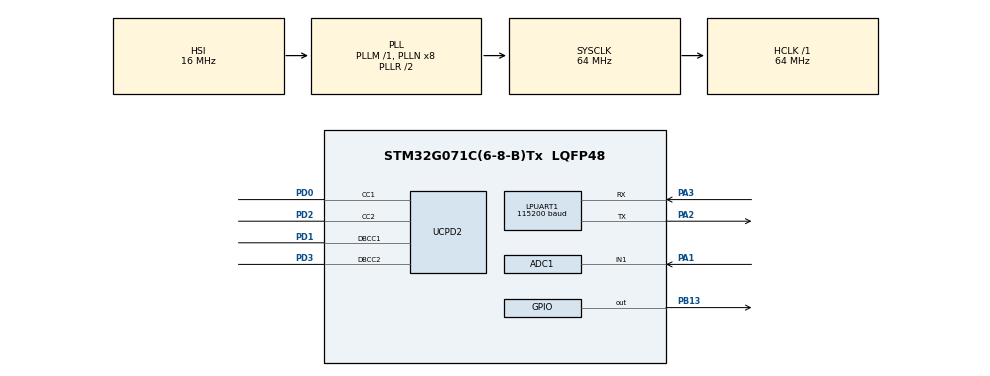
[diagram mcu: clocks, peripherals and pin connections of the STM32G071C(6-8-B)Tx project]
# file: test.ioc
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ADC1.Channel-1\#ChannelRegularConversion=ADC_CHANNEL_1
ADC1.ContinuousConvMode=ENABLE
ADC1.DMAContinuousRequests=ENABLE
ADC1.NbrOfConversion=1
ADC1.NbrOfConversionFlag=1
ADC1.OversamplingMode=DISABLE
ADC1.Rank-1\#ChannelRegularConversion=1
ADC1.SamplingTime-1\#ChannelRegularConversion=ADC_SAMPLINGTIME_COMMON_1
ADC1.SamplingTimeCommon1=ADC_SAMPLETIME_160CYCLES_5
ADC1.SamplingTimeCommon2=ADC_SAMPLETIME_160CYCLES_5
ADC1.master=1
Dma.ADC1.0.Direction=DMA_PERIPH_TO_MEMORY
Dma.ADC1.0.EventEnable=DISABLE
Dma.ADC1.0.Instance=DMA1_Channel1
Dma.ADC1.0.MemDataAlignment=DMA_MDATAALIGN_HALFWORD
Dma.ADC1.0.MemInc=DMA_MINC_ENABLE
Dma.ADC1.0.Mode=DMA_CIRCULAR
Dma.ADC1.0.PeriphDataAlignment=DMA_PDATAALIGN_HALFWORD
Dma.ADC1.0.PeriphInc=DMA_PINC_DISABLE
Dma.ADC1.0.Polarity=HAL_DMAMUX_REQ_GEN_RISING
Dma.ADC1.0.Priority=DMA_PRIORITY_LOW
Dma.ADC1.0.RequestNumber=1
Dma.ADC1.0.SignalID=NONE
Dma.ADC1.0.SyncEnable=DISABLE
Dma.ADC1.0.SyncPolarity=HAL_DMAMUX_SYNC_NO_EVENT
Dma.ADC1.0.SyncRequestNumber=1
Dma.ADC1.0.SyncSignalID=NONE
Dma.LPUART1_TX.3.Direction=DMA_MEMORY_TO_PERIPH
Dma.LPUART1_TX.3.EventEnable=DISABLE
Dma.LPUART1_TX.3.Instance=DMA1_Channel4
Dma.LPUART1_TX.3.MemDataAlignment=DMA_MDATAALIGN_BYTE
Dma.LPUART1_TX.3.MemInc=DMA_MINC_ENABLE
Dma.LPUART1_TX.3.Mode=DMA_NORMAL
Dma.LPUART1_TX.3.PeriphDataAlignment=DMA_PDATAALIGN_BYTE
Dma.LPUART1_TX.3.PeriphInc=DMA_PINC_DISABLE
Dma.LPUART1_TX.3.Polarity=HAL_DMAMUX_REQ_GEN_RISING
Dma.LPUART1_TX.3.Priority=DMA_PRIORITY_LOW
Dma.LPUART1_TX.3.RequestNumber=1
Dma.LPUART1_TX.3.SignalID=NONE
Dma.LPUART1_TX.3.SyncEnable=DISABLE
Dma.LPUART1_TX.3.SyncPolarity=HAL_DMAMUX_SYNC_NO_EVENT
Dma.LPUART1_TX.3.SyncRequestNumber=1
Dma.LPUART1_TX.3.SyncSignalID=NONE
Dma.Request0=ADC1
Dma.Request1=UCPD2_RX
Dma.Request2=UCPD2_TX
Dma.Request3=LPUART1_TX
Dma.UCPD2_RX.1.Direction=DMA_PERIPH_TO_MEMORY
Dma.UCPD2_RX.1.EventEnable=DISABLE
Dma.UCPD2_RX.1.Instance=DMA1_Channel2
Dma.UCPD2_RX.1.MemDataAlignment=DMA_MDATAALIGN_BYTE
Dma.UCPD2_RX.1.MemInc=DMA_MINC_ENABLE
Dma.UCPD2_RX.1.Mode=DMA_NORMAL
Dma.UCPD2_RX.1.PeriphDataAlignment=DMA_PDATAALIGN_BYTE
Dma.UCPD2_RX.1.PeriphInc=DMA_PINC_DISABLE
Dma.UCPD2_RX.1.Polarity=HAL_DMAMUX_REQ_GEN_RISING
Dma.UCPD2_RX.1.Priority=DMA_PRIORITY_LOW
Dma.UCPD2_RX.1.RequestNumber=1
Dma.UCPD2_RX.1.SignalID=NONE
Dma.UCPD2_RX.1.SyncEnable=DISABLE
Dma.UCPD2_RX.1.SyncPolarity=HAL_DMAMUX_SYNC_NO_EVENT
Dma.UCPD2_RX.1.SyncRequestNumber=1
Dma.UCPD2_RX.1.SyncSignalID=NONE
Dma.UCPD2_TX.2.Direction=DMA_MEMORY_TO_PERIPH
Dma.UCPD2_TX.2.EventEnable=DISABLE
Dma.UCPD2_TX.2.Instance=DMA1_Channel3
Dma.UCPD2_TX.2.MemDataAlignment=DMA_MDATAALIGN_BYTE
Dma.UCPD2_TX.2.MemInc=DMA_MINC_ENABLE
Dma.UCPD2_TX.2.Mode=DMA_NORMAL
Dma.UCPD2_TX.2.PeriphDataAlignment=DMA_PDATAALIGN_BYTE
Dma.UCPD2_TX.2.PeriphInc=DMA_PINC_DISABLE
Dma.UCPD2_TX.2.Polarity=HAL_DMAMUX_REQ_GEN_RISING
Dma.UCPD2_TX.2.Priority=DMA_PRIORITY_LOW
Dma.UCPD2_TX.2.RequestNumber=1
Dma.UCPD2_TX.2.SignalID=NONE
Dma.UCPD2_TX.2.SyncEnable=DISABLE
Dma.UCPD2_TX.2.SyncPolarity=HAL_DMAMUX_SYNC_NO_EVENT
Dma.UCPD2_TX.2.SyncRequestNumber=1
Dma.UCPD2_TX.2.SyncSignalID=NONE
FREERTOS.Tasks01=defaultTask,0,128,StartDefaultTask,Default,NULL,Dynamic,NULL,NULL
FREERTOS.configTOTAL_HEAP_SIZE=5000
GUI_INTERFACE.HWBoardVersionName=OtterBoard
GUI_INTERFACE.PDTypeName=V1.0
LPUART1.BaudRate=115200
LPUART1.WordLength=UART_WORDLENGTH_8B
Mcu.Family=STM32G0
Mcu.Name=STM32G071C(6-8-B)Tx
Mcu.Package=LQFP48
Mcu.UserConstants=VDDAAPPLI,3300
NVIC.DMA1_Ch4_7_DMAMUX1_OVR_IRQn=true\:3\:0\:false\:false\:true\:true\:false\:true
NVIC.DMA1_Channel1_IRQn=true\:3\:0\:false\:false\:true\:true\:false\:true
NVIC.DMA1_Channel2_3_IRQn=true\:3\:0\:false\:false\:true\:true\:false\:true
NVIC.UCPD1_2_IRQn=true\:3\:0\:false\:false\:true\:true\:true\:false
NVIC.USART3_4_LPUART1_IRQn=true\:3\:0\:false\:false\:true\:true\:true\:true
PA1.Mode=IN1
PA1.Signal=ADC1_IN1
PA13.Mode=Serial_Wire
PA13.Signal=SYS_SWDIO
PA14-BOOT0.Mode=Serial_Wire
PA14-BOOT0.Signal=SYS_SWCLK
PA2.Mode=Asynchronous
PA2.Signal=LPUART1_TX
PA3.Mode=Asynchronous
PA3.Signal=LPUART1_RX
PB13.Signal=GPIO_Output
PD0.Mode=Sink_AllSignals
PD0.Signal=UCPD2_CC1
PD1.Mode=EnableDeadBattery
PD1.Signal=UCPD2_DBCC1
PD2.Mode=Sink_AllSignals
PD2.Signal=UCPD2_CC2
PD3.Mode=EnableDeadBattery
PD3.Signal=UCPD2_DBCC2
ProjectManager.HeapSize=0x200
ProjectManager.StackSize=0x400
ProjectManager.TargetToolchain=Makefile
RCC.ADCCLockSelection=RCC_ADCCLKSOURCE_PLLADC
RCC.ADCFreq_Value=64000000
RCC.AHBFreq_Value=64000000
RCC.CortexFreq_Value=64000000
RCC.EXTERNAL_CLOCK_VALUE=48000
RCC.HCLKFreq_Value=64000000
RCC.HSE_VALUE=8000000
RCC.HSI_VALUE=16000000
RCC.LSE_VALUE=32768
RCC.SYSCLKFreq_VALUE=64000000
RCC.SYSCLKSource=RCC_SYSCLKSOURCE_PLLCLK
RCC.VCOOutputFreq_Value=128000000
USBPD.PE_SpecRevision_P0=USBPD_SPECIFICATION_REV3
USBPD.PE_SupportedSOPapos_P0=USBPD_SUPPORTED_SOP_SOP1
VP_FREERTOS_VS_CMSIS_V1.Mode=CMSIS_V1
VP_GUI_INTERFACE_VS_gui_interface.Mode=GUI_INTERFACE
VP_SYS_VS_DBSignals.Mode=DisableDeadBatterySignals
VP_TRACER_EMB_VS_traceremb_lpuart1.Mode=TRACER_EMB_LPUART1
VP_USBPD_VS_USBPD2.Mode=USBPD_P0
VP_USBPD_VS_usbpd_tim1.Mode=TIM1
VP_USBPD_VS_usbpd_traceremb.Mode=TRACER_EMB
board=custom

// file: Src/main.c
/* USER CODE BEGIN Header */
/**
  ******************************************************************************
  * @file           : main.c
  * @brief          : Main program body
  ******************************************************************************
  * @attention
  *
  * <h2><center>&copy; Copyright (c) 2020 STMicroelectronics.
  * All rights reserved.</center></h2>
  *
  * This software component is licensed by ST under BSD 3-Clause license,
  * the "License"; You may not use this file except in compliance with the
  * License. You may obtain a copy of the License at:
  *                        opensource.org/licenses/BSD-3-Clause
  *
  ******************************************************************************
  */
/* USER CODE END Header */

#include "main.h"
#include "cmsis_os.h"
#include "usbpd.h"

/* USER CODE BEGIN PM */
uint16_t adc;
float vin;
/* USER CODE END PM */

ADC_HandleTypeDef hadc1;
DMA_HandleTypeDef hdma_adc1;

UART_HandleTypeDef hlpuart1;
DMA_HandleTypeDef hdma_lpuart1_tx;

osThreadId defaultTaskHandle;

void SystemClock_Config(void);
static void MX_GPIO_Init(void);
static void MX_DMA_Init(void);
static void MX_ADC1_Init(void);
static void MX_UCPD2_Init(void);
static void MX_LPUART1_UART_Init(void);
void StartDefaultTask(void const * argument);

int main(void)
{

  /* MCU Configuration--------------------------------------------------------*/

  /* Reset of all peripherals, Initializes the Flash interface and the Systick. */
  HAL_Init();

  /* Configure the system clock */
  SystemClock_Config();

  /* Initialize all configured peripherals */
  MX_GPIO_Init();
  MX_DMA_Init();
  MX_ADC1_Init();
  MX_UCPD2_Init();
  MX_USBPD_Init();
  MX_LPUART1_UART_Init();
  /* USER CODE BEGIN 2 */
  HAL_ADCEx_Calibration_Start(&hadc1);
  HAL_ADC_Start(&hadc1);
  /* USER CODE END 2 */
  /* USBPD initialisation ---------------------------------*/
  MX_USBPD_Init();

  /* Create the thread(s) */
  /* definition and creation of defaultTask */
  osThreadDef(defaultTask, StartDefaultTask, osPriorityNormal, 0, 128);
  defaultTaskHandle = osThreadCreate(osThread(defaultTask), NULL);

  /* Start scheduler */
  osKernelStart();

  /* We should never get here as control is now taken by the scheduler */

  /* Infinite loop */
  while (1)
  {

  }
}

void SystemClock_Config(void)
{
  RCC_OscInitTypeDef RCC_OscInitStruct = {0};
  RCC_ClkInitTypeDef RCC_ClkInitStruct = {0};
  RCC_PeriphCLKInitTypeDef PeriphClkInit = {0};

  /** Configure the main internal regulator output voltage
  */
  HAL_PWREx_ControlVoltageScaling(PWR_REGULATOR_VOLTAGE_SCALE1);
  /** Initializes the CPU, AHB and APB busses clocks
  */
  RCC_OscInitStruct.OscillatorType = RCC_OSCILLATORTYPE_HSI;
  RCC_OscInitStruct.HSIState = RCC_HSI_ON;
  RCC_OscInitStruct.HSIDiv = RCC_HSI_DIV1;
  RCC_OscInitStruct.HSICalibrationValue = RCC_HSICALIBRATION_DEFAULT;
  RCC_OscInitStruct.PLL.PLLState = RCC_PLL_ON;
  RCC_OscInitStruct.PLL.PLLSource = RCC_PLLSOURCE_HSI;
  RCC_OscInitStruct.PLL.PLLM = RCC_PLLM_DIV1;
  RCC_OscInitStruct.PLL.PLLN = 8;
  RCC_OscInitStruct.PLL.PLLP = RCC_PLLP_DIV2;
  RCC_OscInitStruct.PLL.PLLQ = RCC_PLLQ_DIV2;
  RCC_OscInitStruct.PLL.PLLR = RCC_PLLR_DIV2;
  if (HAL_RCC_OscConfig(&RCC_OscInitStruct) != HAL_OK)
  {
    Error_Handler();
  }
  /** Initializes the CPU, AHB and APB busses clocks
  */
  RCC_ClkInitStruct.ClockType = RCC_CLOCKTYPE_HCLK|RCC_CLOCKTYPE_SYSCLK
                              |RCC_CLOCKTYPE_PCLK1;
  RCC_ClkInitStruct.SYSCLKSource = RCC_SYSCLKSOURCE_PLLCLK;
  RCC_ClkInitStruct.AHBCLKDivider = RCC_SYSCLK_DIV1;
  RCC_ClkInitStruct.APB1CLKDivider = RCC_HCLK_DIV1;

  if (HAL_RCC_ClockConfig(&RCC_ClkInitStruct, FLASH_LATENCY_2) != HAL_OK)
  {
    Error_Handler();
  }
  /** Initializes the peripherals clocks
  */
  PeriphClkInit.PeriphClockSelection = RCC_PERIPHCLK_LPUART1|RCC_PERIPHCLK_ADC;
  PeriphClkInit.Lpuart1ClockSelection = RCC_LPUART1CLKSOURCE_PCLK1;
  PeriphClkInit.AdcClockSelection = RCC_ADCCLKSOURCE_PLLADC;
  if (HAL_RCCEx_PeriphCLKConfig(&PeriphClkInit) != HAL_OK)
  {
    Error_Handler();
  }
}

static void MX_ADC1_Init(void)
{

  ADC_ChannelConfTypeDef sConfig = {0};

  /** Configure the global features of the ADC (Clock, Resolution, Data Alignment and number of conversion)
  */
  hadc1.Instance = ADC1;
  hadc1.Init.ClockPrescaler = ADC_CLOCK_SYNC_PCLK_DIV4;
  hadc1.Init.Resolution = ADC_RESOLUTION_12B;
  hadc1.Init.DataAlign = ADC_DATAALIGN_RIGHT;
  hadc1.Init.ScanConvMode = ADC_SCAN_DISABLE;
  hadc1.Init.EOCSelection = ADC_EOC_SINGLE_CONV;
  hadc1.Init.LowPowerAutoWait = DISABLE;
  hadc1.Init.LowPowerAutoPowerOff = DISABLE;
  hadc1.Init.ContinuousConvMode = ENABLE;
  hadc1.Init.NbrOfConversion = 1;
  hadc1.Init.DiscontinuousConvMode = DISABLE;
  hadc1.Init.ExternalTrigConv = ADC_SOFTWARE_START;
  hadc1.Init.ExternalTrigConvEdge = ADC_EXTERNALTRIGCONVEDGE_NONE;
  hadc1.Init.DMAContinuousRequests = DISABLE;
  hadc1.Init.Overrun = ADC_OVR_DATA_PRESERVED;
  hadc1.Init.SamplingTimeCommon1 = ADC_SAMPLETIME_160CYCLES_5;
  hadc1.Init.SamplingTimeCommon2 = ADC_SAMPLETIME_160CYCLES_5;
  hadc1.Init.OversamplingMode = DISABLE;
  hadc1.Init.TriggerFrequencyMode = ADC_TRIGGER_FREQ_HIGH;
  if (HAL_ADC_Init(&hadc1) != HAL_OK)
  {
    Error_Handler();
  }
  /** Configure Regular Channel
  */
  sConfig.Channel = ADC_CHANNEL_1;
  sConfig.Rank = ADC_REGULAR_RANK_1;
  sConfig.SamplingTime = ADC_SAMPLINGTIME_COMMON_1;
  if (HAL_ADC_ConfigChannel(&hadc1, &sConfig) != HAL_OK)
  {
    Error_Handler();
  }

}

static void MX_LPUART1_UART_Init(void)
{

  hlpuart1.Instance = LPUART1;
  hlpuart1.Init.BaudRate = 209700;
  hlpuart1.Init.WordLength = UART_WORDLENGTH_7B;
  hlpuart1.Init.StopBits = UART_STOPBITS_1;
  hlpuart1.Init.Parity = UART_PARITY_NONE;
  hlpuart1.Init.Mode = UART_MODE_TX_RX;
  hlpuart1.Init.HwFlowCtl = UART_HWCONTROL_NONE;
  hlpuart1.Init.OneBitSampling = UART_ONE_BIT_SAMPLE_DISABLE;
  hlpuart1.Init.ClockPrescaler = UART_PRESCALER_DIV1;
  hlpuart1.AdvancedInit.AdvFeatureInit = UART_ADVFEATURE_NO_INIT;
  hlpuart1.FifoMode = UART_FIFOMODE_DISABLE;
  if (HAL_UART_Init(&hlpuart1) != HAL_OK)
  {
    Error_Handler();
  }
  if (HAL_UARTEx_SetTxFifoThreshold(&hlpuart1, UART_TXFIFO_THRESHOLD_1_8) != HAL_OK)
  {
    Error_Handler();
  }
  if (HAL_UARTEx_SetRxFifoThreshold(&hlpuart1, UART_RXFIFO_THRESHOLD_1_8) != HAL_OK)
  {
    Error_Handler();
  }
  if (HAL_UARTEx_DisableFifoMode(&hlpuart1) != HAL_OK)
  {
    Error_Handler();
  }

}

static void MX_UCPD2_Init(void)
{

  /* Peripheral clock enable */
  LL_APB1_GRP1_EnableClock(LL_APB1_GRP1_PERIPH_UCPD2);

  /* UCPD2 DMA Init */

  /* UCPD2_RX Init */
  LL_DMA_SetPeriphRequest(DMA1, LL_DMA_CHANNEL_2, LL_DMAMUX_REQ_UCPD2_RX);

  LL_DMA_SetDataTransferDirection(DMA1, LL_DMA_CHANNEL_2, LL_DMA_DIRECTION_PERIPH_TO_MEMORY);

  LL_DMA_SetChannelPriorityLevel(DMA1, LL_DMA_CHANNEL_2, LL_DMA_PRIORITY_LOW);

  LL_DMA_SetMode(DMA1, LL_DMA_CHANNEL_2, LL_DMA_MODE_NORMAL);

  LL_DMA_SetPeriphIncMode(DMA1, LL_DMA_CHANNEL_2, LL_DMA_PERIPH_NOINCREMENT);

  LL_DMA_SetMemoryIncMode(DMA1, LL_DMA_CHANNEL_2, LL_DMA_MEMORY_INCREMENT);

  LL_DMA_SetPeriphSize(DMA1, LL_DMA_CHANNEL_2, LL_DMA_PDATAALIGN_BYTE);

  LL_DMA_SetMemorySize(DMA1, LL_DMA_CHANNEL_2, LL_DMA_MDATAALIGN_BYTE);

  /* UCPD2_TX Init */
  LL_DMA_SetPeriphRequest(DMA1, LL_DMA_CHANNEL_3, LL_DMAMUX_REQ_UCPD2_TX);

  LL_DMA_SetDataTransferDirection(DMA1, LL_DMA_CHANNEL_3, LL_DMA_DIRECTION_MEMORY_TO_PERIPH);

  LL_DMA_SetChannelPriorityLevel(DMA1, LL_DMA_CHANNEL_3, LL_DMA_PRIORITY_LOW);

  LL_DMA_SetMode(DMA1, LL_DMA_CHANNEL_3, LL_DMA_MODE_NORMAL);

  LL_DMA_SetPeriphIncMode(DMA1, LL_DMA_CHANNEL_3, LL_DMA_PERIPH_NOINCREMENT);

  LL_DMA_SetMemoryIncMode(DMA1, LL_DMA_CHANNEL_3, LL_DMA_MEMORY_INCREMENT);

  LL_DMA_SetPeriphSize(DMA1, LL_DMA_CHANNEL_3, LL_DMA_PDATAALIGN_BYTE);

  LL_DMA_SetMemorySize(DMA1, LL_DMA_CHANNEL_3, LL_DMA_MDATAALIGN_BYTE);

  /* UCPD2 interrupt Init */
  NVIC_SetPriority(UCPD1_2_IRQn, 3);
  NVIC_EnableIRQ(UCPD1_2_IRQn);

}

static void MX_DMA_Init(void)
{

  /* DMA controller clock enable */
  __HAL_RCC_DMA1_CLK_ENABLE();

  /* DMA interrupt init */
  /* DMA1_Channel1_IRQn interrupt configuration */
  HAL_NVIC_SetPriority(DMA1_Channel1_IRQn, 3, 0);
  HAL_NVIC_EnableIRQ(DMA1_Channel1_IRQn);
  /* DMA1_Channel2_3_IRQn interrupt configuration */
  NVIC_SetPriority(DMA1_Channel2_3_IRQn, 3);
  NVIC_EnableIRQ(DMA1_Channel2_3_IRQn);
  /* DMA1_Ch4_7_DMAMUX1_OVR_IRQn interrupt configuration */
  HAL_NVIC_SetPriority(DMA1_Ch4_7_DMAMUX1_OVR_IRQn, 3, 0);
  HAL_NVIC_EnableIRQ(DMA1_Ch4_7_DMAMUX1_OVR_IRQn);

}

static void MX_GPIO_Init(void)
{
  GPIO_InitTypeDef GPIO_InitStruct = {0};

  /* GPIO Ports Clock Enable */
  __HAL_RCC_GPIOA_CLK_ENABLE();
  __HAL_RCC_GPIOB_CLK_ENABLE();
  __HAL_RCC_GPIOD_CLK_ENABLE();

  /*Configure GPIO pin Output Level */
  HAL_GPIO_WritePin(GPIOB, GPIO_PIN_13, GPIO_PIN_RESET);

  /*Configure GPIO pin : PB13 */
  GPIO_InitStruct.Pin = GPIO_PIN_13;
  GPIO_InitStruct.Mode = GPIO_MODE_OUTPUT_PP;
  GPIO_InitStruct.Pull = GPIO_NOPULL;
  GPIO_InitStruct.Speed = GPIO_SPEED_FREQ_LOW;
  HAL_GPIO_Init(GPIOB, &GPIO_InitStruct);

}

void StartDefaultTask(void const * argument)
{
  for(;;)
  {
    osDelay(1);
  }
}

void Error_Handler(void)
{
}

/************************ (C) COPYRIGHT STMicroelectronics *****END OF FILE****/
